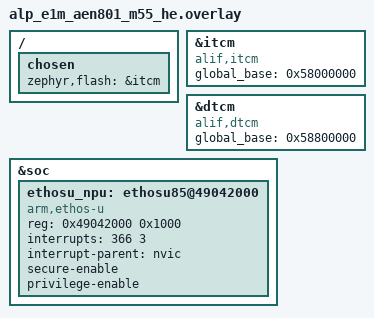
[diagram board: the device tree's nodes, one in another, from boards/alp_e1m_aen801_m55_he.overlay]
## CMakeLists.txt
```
# Copyright (c) 2026 Alp Lab AB
# SPDX-License-Identifier: Apache-2.0
#
# aen-npu-inference-alif -- the MATCHED-RUNTIME NPU inference app for the
# E1M-AEN801 (Ensemble E8, M55-HE).  A Vela-compiled int8 model runs through
# the Arm Apache-2.0 InferenceProcess wrapper (lib/ethosu_utils, the same
# runtime Alif's tflm_ethosu / executorch samples use) -> TFLM MicroInterpreter
# with AddEthosU() -> ethosu_invoke onto the Ethos-U85 (256-MAC).
#
# DIFFERENCE vs the sibling aen-npu-inference (which returned ethosu_invoke=1):
#   Both apps now enable CONFIG_ALP_SDK_INFERENCE_BACKEND_ETHOS_U_AEN
#   (prj.conf), which links alp-sdk's AEN Ethos-U backend
#   (src/backends/inference/ethos_u_aen.cpp) and its strong
#   ethosu_address_remap()/ethosu_config_select() overrides -- the actual fix,
#   measured 2026-07-28.  CONFIG_ARM_ETHOS_U (hal_alif's stale-signature
#   ethosu_callback.c) is deliberately NOT used by either app; see prj.conf.
#   This app additionally supports Vela-compiling with the ALIF system-config
#   (--config <ensemble_vela.ini> --system-config Ethos_U85_SRAM_Only
#   --memory-mode Sram_Only) via -DAEN_NPU_VELA_CONFIG, to match the
#   bench-validated command-stream layout exactly -- see gen_model.py for why
#   that config is NOT itself the ethosu_invoke=1 fix.  The overlay
#   re-`compatible`s the itcm/dtcm nodes onto alif,itcm/alif,dtcm and adds the
#   global_base props local_to_global() needs.
#
# Modules required at build time (pass via -DEXTRA_ZEPHYR_MODULES):
#   the alp-sdk checkout    (the SDK + ARM_ETHOS_U glue)
#   hal_alif                (the Alif HAL module -- ethosu_callback.c)
#   hal/ethos_u             (the Arm Ethos-U core driver lib)
#   lib/tflite-micro        (TFLM + the Ethos-U custom op)
#
# LICENSING (alp-sdk doctrine):
#   - lib/ethosu_utils/{inference_process.cpp,.hpp} + include/ethosu/InferenceRunner.h
#     are Apache-2.0 (Arm) -> VENDORED into this example (Tier-2, provenance hdr).
#   - The Alif Vela config (ensemble_vela.ini) + the subsys/modules/ethosu glue
#     are ALIF PROPRIETARY -> NOT vendored and NOT redistributed by alp-sdk.
#     Obtain ensemble_vela.ini from alp-sdk-internal and pass it explicitly:
#       -DAEN_NPU_VELA_CONFIG=<alp-sdk-internal>/.../ensemble_vela.ini
#     Without it Vela falls back to its built-in system-config and the emitted
#     command stream will NOT match the bench-validated E8 RTSS-HE runtime.

cmake_minimum_required(VERSION 3.20.0)

find_package(Zephyr REQUIRED HINTS $ENV{ZEPHYR_BASE})
project(aen_npu_inference_alif LANGUAGES C CXX)

# --------------------------------------------------------------------------
# Model-gen: Vela-compile the fixture for the U85 with the Alif system-config.
# --------------------------------------------------------------------------
set(AEN_NPU_VELA   "vela"
    CACHE FILEPATH "Vela compiler executable (on PATH, or override: -DAEN_NPU_VELA=<venv>/bin/vela)")
set(AEN_NPU_ACCEL  "ethos-u85-256"
    CACHE STRING   "Vela --accelerator-config (the AEN801 U85 is 256-MAC)")
set(AEN_NPU_MODEL  "${CMAKE_CURRENT_SOURCE_DIR}/../../../tests/fixtures/models/tiny_int8.tflite"
    CACHE FILEPATH "Input int8 .tflite to Vela-compile")
set(AEN_NPU_MODEL_NAME "tiny_int8_fixture"
    CACHE STRING   "Embedded model identity string")

# ALIF PROPRIETARY Vela config -- NOT redistributed by alp-sdk.  Obtain it from
# alp-sdk-internal and pass it via -DAEN_NPU_VELA_CONFIG=<path>/ensemble_vela.ini.
# When unset, Vela uses its built-in system-config (does NOT match the bench).
set(AEN_NPU_VELA_CONFIG ""
    CACHE FILEPATH "Path to the Alif Vela config .ini (ALIF PROPRIETARY -- from alp-sdk-internal)")
if(NOT AEN_NPU_VELA_CONFIG)
	message(WARNING
		"aen-npu-inference-alif: AEN_NPU_VELA_CONFIG unset -- Vela will use its "
		"built-in system-config and the emitted command stream will NOT match the "
		"bench-validated E8 runtime.  Pass -DAEN_NPU_VELA_CONFIG=<alp-sdk-internal>/ensemble_vela.ini.")
endif()
set(AEN_NPU_SYSTEM_CONFIG "Ethos_U85_SRAM_Only"
    CACHE STRING   "Vela --system-config (HE core, single SRAM region)")
set(AEN_NPU_MEMORY_MODE   "Sram_Only"
    CACHE STRING   "Vela --memory-mode (single region -> SRAM0)")

set(AEN_NPU_GEN_DIR "${CMAKE_CURRENT_BINARY_DIR}/model-gen")
set(AEN_NPU_MODEL_H "${AEN_NPU_GEN_DIR}/model.h")

set(_gen_args
	--vela          ${AEN_NPU_VELA}
	--accel         ${AEN_NPU_ACCEL}
	--model         ${AEN_NPU_MODEL}
	--name          ${AEN_NPU_MODEL_NAME}
	--build-dir     ${AEN_NPU_GEN_DIR}
	--out           ${AEN_NPU_MODEL_H}
)
# --system-config/--memory-mode name sections that live ONLY in the Alif
# proprietary ensemble_vela.ini (e.g. Ethos_U85_SRAM_Only) -- pass them ONLY
# when that config is supplied, else Vela errors "Section ... not found" against
# its built-in vela.ini.  Without the Alif config Vela falls back to its default
# system-config (the build succeeds; the command stream just won't match bench).
if(AEN_NPU_VELA_CONFIG)
	list(APPEND _gen_args --config ${AEN_NPU_VELA_CONFIG}
	     --system-config ${AEN_NPU_SYSTEM_CONFIG} --memory-mode ${AEN_NPU_MEMORY_MODE})
endif()

add_custom_command(
	OUTPUT  ${AEN_NPU_MODEL_H}
	COMMAND ${CMAKE_COMMAND} -E make_directory ${AEN_NPU_GEN_DIR}
	COMMAND ${PYTHON_EXECUTABLE} ${CMAKE_CURRENT_SOURCE_DIR}/gen_model.py ${_gen_args}
	DEPENDS ${AEN_NPU_MODEL} ${CMAKE_CURRENT_SOURCE_DIR}/gen_model.py
	COMMENT "aen-npu-inference-alif: Vela-compiling ${AEN_NPU_MODEL} for ${AEN_NPU_ACCEL} (${AEN_NPU_SYSTEM_CONFIG})"
	VERBATIM
)

# Configure-time generation (so the include path resolves on the first build).
if(NOT EXISTS ${AEN_NPU_MODEL_H})
	execute_process(
		COMMAND ${CMAKE_COMMAND} -E make_directory ${AEN_NPU_GEN_DIR}
		COMMAND ${PYTHON_EXECUTABLE} ${CMAKE_CURRENT_SOURCE_DIR}/gen_model.py ${_gen_args}
		RESULT_VARIABLE _gen_rc
	)
	if(NOT _gen_rc EQUAL 0)
		message(FATAL_ERROR "aen-npu-inference-alif: model-gen failed (rc=${_gen_rc})")
	endif()
endif()

add_custom_target(aen_npu_model DEPENDS ${AEN_NPU_MODEL_H})
add_dependencies(app aen_npu_model)

# --------------------------------------------------------------------------
# Publish hal_alif's common/include on the GLOBAL Zephyr include path so
# alp-sdk's AEN Ethos-U backend (src/backends/inference/ethos_u_aen.cpp,
# enabled by CONFIG_ALP_SDK_INFERENCE_BACKEND_ETHOS_U_AEN in prj.conf) can
# #include <soc_memory_map.h> (the local_to_global() its strong
# ethosu_address_remap uses).  NOT the hal_alif ethosu_callback.c library --
# that stays off (CONFIG_ARM_ETHOS_U unset, see prj.conf).
#
# WHY HERE and not via CONFIG_RTSS_HE: hal_alif's common/CMakeLists.txt adds
# that include dir only under `if(CONFIG_RTSS_HE OR CONFIG_RTSS_HP)`, but that
# same gate also compiles the TrustZone sources sau_tcm_ns_setup.c / tgu.c,
# which hard-#error without a non-secure `ns` DTS node (the fork has one; this
# RAM-run board does not, and inventing one would be inventing HW config).  We
# therefore publish ONLY the header directory and leave the TZ sources off.
# zephyr_include_directories() adds to the global interface, so the header is
# visible to the alp-sdk ethos_u_aen.cpp TU as well as the app.
zephyr_include_directories(${ZEPHYR_ALIF_MODULE_DIR}/common/include)

target_include_directories(app PRIVATE ${AEN_NPU_GEN_DIR})

# Apache-2.0 Arm InferenceProcess wrapper (vendored into this example).
target_include_directories(app PRIVATE ${CMAKE_CURRENT_SOURCE_DIR}/ethosu_utils)
target_sources(app PRIVATE
	src/main.cpp
	ethosu_utils/inference_process.cpp
)
```

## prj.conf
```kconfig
# SPDX-License-Identifier: Apache-2.0
#
# aen-npu-inference-alif -- MATCHED-RUNTIME FULL NPU inference on the
# E1M-AEN801 (Ensemble E8, M55-HE): a Vela-compiled int8 model (Alif
# system-config) through the Arm Apache InferenceProcess wrapper + TFLM's
# MicroInterpreter onto the Ethos-U85 (256-MAC), with the hal_alif Ethos-U
# callback linked.  Bench RAM-run over the Alp UART console (E1M edge UART0).

# --- TFLM + Ethos-U stack ---------------------------------------------------

# TFLM is C++17; the InferenceProcess wrapper + MicroInterpreter are C++.
CONFIG_CPP=y
CONFIG_STD_CPP17=y
# The Arm InferenceProcess wrapper uses std::string / std::vector / std::queue.
CONFIG_REQUIRES_FULL_LIBCPP=y

# TFLM module (MicroInterpreter, op resolver, reference kernels, and -- because
# the Ethos-U driver is enabled -- the Ethos-U custom-op kernel ethosu.cc whose
# Register_ETHOSU() -> ethosu_invoke dispatches onto the NPU).
CONFIG_TENSORFLOW_LITE_MICRO=y

# THE KEY DRIVER.  CONFIG_ETHOS_U compiles the Arm Ethos-U core driver
# (ethosu_driver.c / ethosu_device_u85.c -> ethosu_invoke + the NPU command
# stream) and the Zephyr frontend (drivers/misc/ethos_u, ETHOS_U_ARM, which
# auto-instantiates the arm,ethos-u node at POST_KERNEL).
CONFIG_ETHOS_U=y

# THE STRONG REMAP -- but NOT via hal_alif's ethosu_callback.c.
#
# CONFIG_ARM_ETHOS_U is the symbol hal_alif's drivers/CMakeLists.txt gates its
# ethosu_callback.c on (alp-sdk defines it in zephyr/Kconfig).  That file does
# carry the strong ethosu_address_remap = local_to_global we need -- BUT it was
# written against an OLDER Arm core driver and ALSO defines
# ethosu_flush_dcache / ethosu_invalidate_dcache with the OLD signature
# (uint32_t *p, size_t bytes).  The pinned hal_ethos_u core driver uses the NEW
# signature (const uint64_t *base_addr, const size_t *base_addr_size, int n) and
# upstream Zephyr's ethos_u_common.c provides matching strong versions, so
# compiling ethosu_callback.c causes a duplicate-symbol link error AND, if it
# won, the core driver would call its dcache hooks with mismatched args.
#
# So we keep ARM_ETHOS_U OFF (do not compile the stale vendor callback).  The
# strong ethosu_address_remap = local_to_global() now lives in alp-sdk's AEN
# Ethos-U backend (src/backends/inference/ethos_u_aen.cpp, enabled below) --
# it overrides the core driver's weak identity remap the same way, without
# the stale vendor file's dcache-hook clash.  local_to_global() itself is
# hal_alif's (soc_memory_map.h) -- nothing is re-authored.  The correct-
# signature dcache hooks come from upstream ethos_u_common.c (ETHOS_U_DCACHE
# below).  CONFIG_ARM_ETHOS_U is intentionally NOT set.

# alp-sdk AEN Ethos-U backend -- supplies the strong ethosu_address_remap()/
# ethosu_config_select() overrides (see src/backends/inference/ethos_u_aen.cpp).
# This app drives inference through the raw InferenceProcess wrapper, not
# <alp/inference.h>, but Zephyr links every alp-sdk TU with --whole-archive,
# so enabling the backend here is sufficient to link the overrides in.
CONFIG_ALP_SDK=y
CONFIG_ALP_SDK_INFERENCE_BACKEND_TFLM=y
CONFIG_ALP_SDK_INFERENCE_BACKEND_ETHOS_U_AEN=y
CONFIG_ALP_SDK_INFERENCE_ETHOS_U_VARIANT_U85=y

# Use upstream Zephyr's correct-signature cache hooks (ethos_u_common.c).  They
# are architectural no-ops under CONFIG_DCACHE=n, but keep the strong/weak
# resolution unambiguous and ready for a future DCACHE=y re-enable.
CONFIG_ETHOS_U_DCACHE=y

# NPU variant: the AE822 (E8) NPU is an Ethos-U85; pick the 256-MAC config so
# the core driver compiles ethosu_device_u85.c and the Vela ethos-u85-256
# command stream matches the silicon.  Agrees with gen_model.py --accel and
# the Alif --system-config Ethos_U85_SRAM_Only.
CONFIG_ETHOS_U85_256=y

# --- Heap / stack -----------------------------------------------------------

# TFLM + the Ethos-U Zephyr glue + the InferenceProcess wrapper allocate from
# the system heap (k_malloc for the per-thread heap/stacks/queue nodes).
CONFIG_HEAP_MEM_POOL_SIZE=65536

# AllocateTensors + Invoke run with the InferenceProcess on the main thread
# here (single job, no worker thread); give it the upstream sample's headroom.
CONFIG_MAIN_STACK_SIZE=16384

# --- DMA correctness (the #1 bench risk) ------------------------------------

# The Ethos-U is a DMA master reading the model + arena out of SRAM0.  With the
# M55 D-cache on, the CPU could leave the model/input dirty in cache or read
# stale output.  The hal_alif callback DOES provide clean/invalidate hooks
# (ethosu_flush/invalidate_dcache), but on this bench RAM-run we keep DCACHE=n
# (the eth_dwmac approach) so the NPU and CPU share a coherent view with no
# maintenance dependency.  (Follow-up: re-enable DCACHE -- the matched runtime's
# flush/invalidate hooks are already linked via ethosu_callback.c.)
CONFIG_DCACHE=n

# --- Console ----------------------------------------------------------------
# Console: Alp UART console -- E1M edge UART0 (Alif UART5, P3_4/P3_5, 115200
# 8N1, NS16550), the E1M-AEN801 carrier console. The board _defconfig already
# selects it; we set it explicitly here so the example is self-describing.
CONFIG_SERIAL=y
CONFIG_CONSOLE=y
CONFIG_UART_CONSOLE=y
CONFIG_UART_INTERRUPT_DRIVEN=y
# Serial-less bench? Comment the four lines above and uncomment these to read
# 'ram_console_buf' over SWD instead:
# CONFIG_RAM_CONSOLE=y
# CONFIG_RAM_CONSOLE_BUFFER_SIZE=2048
# CONFIG_UART_CONSOLE=n
CONFIG_PRINTK=y
# Keep logging off so the single RESULT line prints cleanly without log
# interleaving; the PASS gate reads that printk line, not log output.
CONFIG_LOG=n
```

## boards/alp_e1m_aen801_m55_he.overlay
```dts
/*
 * Copyright (c) 2026 Alp Lab AB
 * SPDX-License-Identifier: Apache-2.0
 *
 * aen-npu-inference-alif overlay for the E1M-AEN801 (Ensemble E8, M55-HE)
 * RAM-run -- the MATCHED-RUNTIME NPU inference overlay.  Adds:
 *   1. the Arm Ethos-U85 NPU node (base 0x49042000, IRQ 366);
 *   2. global_base on the ITCM/DTCM nodes (the missing piece for
 *      soc_memory_map.h local_to_global());
 *   3. the ITCM RAM-run chosen retarget.
 *
 * =====================  THE #1 BENCH RISK: DMA PLACEMENT  ====================
 * The Ethos-U85 is a DMA bus master: it reads the Vela command stream + weights
 * (the embedded model) and the intermediate tensors (the TFLM arena) over its
 * own AXI master, and writes the output tensor back the same way.  Those buffers
 * MUST live in memory the NPU can reach, and at the address the NPU is PROGRAMMED
 * with -- which is where local_to_global() comes in.
 *
 * The generated M55-HE board sets `zephyr,sram = &dtcm`.  DTCM is private to the
 * CPU; the model + arena are therefore tagged into the "SRAM0" linker region
 * (global on-chip SRAM @0x02000000, declared by the SoC dtsi sram0 node).  SRAM0
 * is already a global system address, so local_to_global() returns it unchanged
 * -- but for any ITCM/DTCM-resident buffer the strong remap is what converts the
 * CPU-local pointer into the global address the NPU's AXI master needs.
 * Combined with CONFIG_DCACHE=n (prj.conf), the CPU and NPU share a coherent
 * view of SRAM0 with no cache-maintenance calls.
 * ============================================================================
 */

/*
 * RAM-run: the SoC `select` puts code in XIP; retarget ROM to ITCM so the image
 * links + runs from RAM (J-Link loadbin+go, no reset).  PATH-REFERENCE form
 * (&itcm) -- the phandle-array form <&itcm> makes FLASH_SIZE=0 and overflows the
 * link.  Same as the regcheck overlay.
 */
/ {
	chosen {
		zephyr,flash = &itcm;
		/delete-property/ zephyr,code-partition;
	};
};

/*
 * global_base for local_to_global().
 *
 * hal_alif's soc_memory_map.h does DT_PROP(DT_NODELABEL(itcm), global_base) and
 * DT_PROP(DT_NODELABEL(dtcm), global_base).  The board's upstream itcm/dtcm
 * nodes are compatible "arm,itcm"/"arm,dtcm", whose binding has no global_base,
 * so the property is both undeclared and absent.  Re-`compatible` the nodes onto
 * the alp-sdk alif,itcm/alif,dtcm bindings (which declare global_base) and set
 * the E8 RTSS-HE global views, transcribed from the Apache-2.0 zephyr_alif fork
 * (dts/arm/alif/ensemble/common/ensemble_rtss_he.dtsi):
 *     ITCM global_base = 0x58000000, DTCM global_base = 0x58800000.
 * The zephyr,memory-region / reg are unchanged so the linker regions and the
 * RAM-run flash retarget above are unaffected.
 */
&itcm {
	compatible = "alif,itcm";
	global_base = <0x58000000>;
};

&dtcm {
	compatible = "alif,dtcm";
	global_base = <0x58800000>;
};

&soc {
	/*
	 * Arm Ethos-U85 NPU.  compatible "arm,ethos-u" (binding arm,ethos-u.yaml),
	 * driven by the Arm Ethos-U core driver's Zephyr frontend
	 * (drivers/misc/ethos_u/ethos_u_arm.c, DT_DRV_COMPAT arm_ethos_u).
	 * status="okay" makes DT_HAS_ARM_ETHOS_U_ENABLED true, which both builds
	 * the frontend and -- via CONFIG_ARM_ETHOS_U's `depends on` -- gates the
	 * NPU driver in.  ethosu_init() runs the NPU soft-reset before main(); the
	 * TFLM Ethos-U kernel later grabs this driver instance via
	 * ethosu_reserve_driver() inside Invoke().
	 *
	 * IRQ 366 + secure/privilege flags transcribed verbatim from the fork node
	 * (e4_e6_e8.dtsi ethosu1).  No `clocks` property: the fork's ethosu85 node
	 * carries none -- regcheck already confirmed the block is clocked
	 * (device_is_ready=1, ID=0x20007001).
	 */
	ethosu_npu: ethosu85@49042000 {
		compatible = "arm,ethos-u";
		reg = <0x49042000 0x1000>;
		interrupts = <366 3>;
		interrupt-parent = <&nvic>;
		secure-enable;
		privilege-enable;
		status = "okay";
	};
};
```

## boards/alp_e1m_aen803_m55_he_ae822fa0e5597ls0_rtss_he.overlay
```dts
/*
 * Copyright (c) 2026 Alp Lab AB
 * SPDX-License-Identifier: Apache-2.0
 *
 * aen-npu-inference-alif overlay for the E1M-AEN803 (Ensemble E8, M55-HE)
 * RAM-run -- the MATCHED-RUNTIME NPU inference overlay.  Adds:
 *   1. the Arm Ethos-U85 NPU node (base 0x49042000, IRQ 366);
 *   2. global_base on the ITCM/DTCM nodes (the missing piece for
 *      soc_memory_map.h local_to_global());
 *   3. the ITCM RAM-run chosen retarget.
 *
 * =====================  THE #1 BENCH RISK: DMA PLACEMENT  ====================
 * The Ethos-U85 is a DMA bus master: it reads the Vela command stream + weights
 * (the embedded model) and the intermediate tensors (the TFLM arena) over its
 * own AXI master, and writes the output tensor back the same way.  Those buffers
 * MUST live in memory the NPU can reach, and at the address the NPU is PROGRAMMED
 * with -- which is where local_to_global() comes in.
 *
 * The generated M55-HE board sets `zephyr,sram = &dtcm`.  DTCM is private to the
 * CPU; the model + arena are therefore tagged into the "SRAM0" linker region
 * (global on-chip SRAM @0x02000000, declared by the SoC dtsi sram0 node).  SRAM0
 * is already a global system address, so local_to_global() returns it unchanged
 * -- but for any ITCM/DTCM-resident buffer the strong remap is what converts the
 * CPU-local pointer into the global address the NPU's AXI master needs.
 * Combined with CONFIG_DCACHE=n (prj.conf), the CPU and NPU share a coherent
 * view of SRAM0 with no cache-maintenance calls.
 * ============================================================================
 */

/*
 * RAM-run: the SoC `select` puts code in XIP; retarget ROM to ITCM so the image
 * links + runs from RAM (J-Link loadbin+go, no reset).  PATH-REFERENCE form
 * (&itcm) -- the phandle-array form <&itcm> makes FLASH_SIZE=0 and overflows the
 * link.  Same as the regcheck overlay.
 */
/ {
	chosen {
		zephyr,flash = &itcm;
		/delete-property/ zephyr,code-partition;
	};
};

/*
 * global_base for local_to_global().
 *
 * hal_alif's soc_memory_map.h does DT_PROP(DT_NODELABEL(itcm), global_base) and
 * DT_PROP(DT_NODELABEL(dtcm), global_base).  The board's upstream itcm/dtcm
 * nodes are compatible "arm,itcm"/"arm,dtcm", whose binding has no global_base,
 * so the property is both undeclared and absent.  Re-`compatible` the nodes onto
 * the alp-sdk alif,itcm/alif,dtcm bindings (which declare global_base) and set
 * the E8 RTSS-HE global views, transcribed from the Apache-2.0 zephyr_alif fork
 * (dts/arm/alif/ensemble/common/ensemble_rtss_he.dtsi):
 *     ITCM global_base = 0x58000000, DTCM global_base = 0x58800000.
 * The zephyr,memory-region / reg are unchanged so the linker regions and the
 * RAM-run flash retarget above are unaffected.
 */
&itcm {
	compatible = "alif,itcm";
	global_base = <0x58000000>;
};

&dtcm {
	compatible = "alif,dtcm";
	global_base = <0x58800000>;
};

&soc {
	/*
	 * Arm Ethos-U85 NPU.  compatible "arm,ethos-u" (binding arm,ethos-u.yaml),
	 * driven by the Arm Ethos-U core driver's Zephyr frontend
	 * (drivers/misc/ethos_u/ethos_u_arm.c, DT_DRV_COMPAT arm_ethos_u).
	 * status="okay" makes DT_HAS_ARM_ETHOS_U_ENABLED true, which both builds
	 * the frontend and -- via CONFIG_ARM_ETHOS_U's `depends on` -- gates the
	 * NPU driver in.  ethosu_init() runs the NPU soft-reset before main(); the
	 * TFLM Ethos-U kernel later grabs this driver instance via
	 * ethosu_reserve_driver() inside Invoke().
	 *
	 * IRQ 366 + secure/privilege flags transcribed verbatim from the fork node
	 * (e4_e6_e8.dtsi ethosu1).  No `clocks` property: the fork's ethosu85 node
	 * carries none -- regcheck already confirmed the block is clocked
	 * (device_is_ready=1, ID=0x20007001).
	 */
	ethosu_npu: ethosu85@49042000 {
		compatible = "arm,ethos-u";
		reg = <0x49042000 0x1000>;
		interrupts = <366 3>;
		interrupt-parent = <&nvic>;
		secure-enable;
		privilege-enable;
		status = "okay";
	};
};
```

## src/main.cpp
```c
/*
 * Copyright (c) 2026 Alp Lab AB
 * SPDX-License-Identifier: Apache-2.0
 *
 * aen-npu-inference-alif -- MATCHED-RUNTIME on-silicon FULL NPU inference on the
 * E1M-AEN801 (Ensemble E8, M55-HE).  A Vela-compiled int8 model (compiled with
 * the ALIF system-config Ethos_U85_SRAM_Only) runs through the Arm Apache-2.0
 * InferenceProcess wrapper (lib/ethosu_utils -- the SAME runtime Alif's
 * tflm_ethosu / executorch samples use), which drives TFLM's MicroInterpreter
 * with AddEthosU() so the fused subgraph dispatches onto the Ethos-U85
 * (256-MAC) via ethosu_invoke.
 *
 * WHY THIS RUNS WHERE aen-npu-inference RETURNED ethosu_invoke=1:
 *   The Arm Ethos-U core driver's weak ethosu_address_remap()/
 *   ethosu_config_select() defaults leave ITCM/DTCM addresses untranslated and
 *   route the command stream + regions to the EXT AXI port -- wrong for this
 *   board's all-in-SRAM0 layout (bus-aborts on the first NPU fetch).  The fix
 *   is alp-sdk's AEN Ethos-U backend (src/backends/inference/ethos_u_aen.cpp),
 *   which supplies the STRONG overrides; CONFIG_ALP_SDK_INFERENCE_BACKEND_
 *   ETHOS_U_AEN=y (prj.conf) links it in -- see that file for the full
 *   explanation of both overrides, moved there from this file's previous
 *   in-app copies (measured 2026-07-28: the Vela --memory-mode flag alone is
 *   NOT the fix -- a byte-identical command stream to this app's sibling still
 *   returned ethosu_invoke=1 without the address-remap/config-select overrides).
 *
 * WHAT THIS PROVES (and what it does NOT):
 *   It proves the full matched path: a Vela-compiled .tflite ->
 *   InferenceProcess::runJob -> tflite::GetModel() -> MicroMutableOpResolver
 *   with AddEthosU() -> MicroInterpreter::Invoke() -> ethosu_invoke -> the NPU.
 *   A runJob()==false (success) + a populated output tensor is the "real
 *   inference ran on the NPU" evidence.
 *
 *   It does NOT validate model *accuracy* -- the embedded model is the in-tree
 *   FIXTURE tiny_int8.tflite (Vela: 1 NPU op, 100% NPU, 8 MACs), chosen so the
 *   bench app is hermetic and small.  A real-model end-to-end is the documented
 *   follow-up: rebuild with -DAEN_NPU_MODEL=<real.tflite>; the RESULT contract
 *   is model-agnostic.
 *
 * HOW WE OBSERVE (mirrors the regcheck dual-path):
 *   1. main() prints one RESULT PASS/FAIL line to the RAM console (read
 *      'ram_console_buf' over J-Link mem8, ASCII-decode).
 *   2. The same evidence is latched into file-scope volatile globals so it is
 *      readable by symbol over SWD even if the console were not captured.
 *
 * DMA placement: the model + arena live in SRAM0 (global on-chip SRAM
 * @0x02000000), NOT the M55-HE DTCM, because the NPU DMA cannot reach DTCM.
 * Combined with CONFIG_DCACHE=n, the CPU and NPU share a coherent view.  See
 * the overlay + gen_model.py.
 */

#include <cstdint>
#include <cstring>
#include <string>
#include <vector>

#include <zephyr/kernel.h>
#include <zephyr/device.h>
#include <zephyr/devicetree.h>
#include <zephyr/sys/printk.h>

/* Arm Apache-2.0 InferenceProcess wrapper (vendored: ethosu_utils/). */
#include "inference_process.hpp"

/* Generated by gen_model.py: networkModelData[] (rodata), NETWORK_MODEL_LEN,
 * NETWORK_MODEL_NAME, TENSOR_ARENA_SIZE, and the SRAM0 placement macros. */
#include "model.h"

using namespace InferenceProcess;

/* The Ethos-U node added by boards/alp_e1m_aen801_m55_he_ae822fa0e5597ls0_rtss_he.overlay. */
#define NPU_NODE DT_NODELABEL(ethosu_npu)

/*
 * The strong ethosu_address_remap()/ethosu_config_select() overrides that
 * make ethosu_invoke succeed on this board (NPU AXI address translation +
 * SRAM-port MEM_ATTR routing) used to live here.  They are now owned by
 * alp-sdk's AEN Ethos-U backend -- see src/backends/inference/ethos_u_aen.cpp
 * for the full explanation (WEAK-default behaviour, why it is wrong for an
 * all-in-SRAM0 layout, the bench-confirmed fault signature) and
 * CONFIG_ALP_SDK_INFERENCE_BACKEND_ETHOS_U_AEN in this app's prj.conf for how
 * they get linked into a build that never calls <alp/inference.h>.
 */

/*
 * Tensor arena -- DMA-reachable SRAM0, 16-byte aligned (NPU access
 * granularity).  TENSOR_ARENA_ATTR = __aligned(16) section("SRAM0").  This is
 * the working memory the MicroInterpreter (inside InferenceProcess) hands to
 * both the CPU reference kernels and the Ethos-U op; it MUST be NPU-reachable.
 */
TENSOR_ARENA_ATTR static uint8_t tensor_arena[TENSOR_ARENA_SIZE];

/*
 * DMA-reachable copy of the model.  networkModelData[] is const rodata
 * (initialized, in ITCM/flash); the Ethos-U reads the fused command stream +
 * weights out of the model via its own AXI master, so the bytes it executes
 * MUST live in NPU-reachable SRAM0.  An *initialized* array placed directly in
 * the SRAM0 custom section is NOT init-copied by Zephyr -> garbage -> bus
 * fault.  So keep the model in rodata and memcpy it into this uninitialized
 * SRAM0 buffer at startup.
 */
static uint8_t model_sram[NETWORK_MODEL_LEN] __aligned(NPU_ALIGN) __attribute__((section("SRAM0")));

/* Output capture buffer (SRAM0 -- the NPU writes the output tensor via DMA). */
static uint8_t output_sram[256] __aligned(NPU_ALIGN) __attribute__((section("SRAM0")));

/*
 * Latched evidence, readable by symbol over SWD independent of the RAM-console
 * decode.  volatile so the stores are not optimised away.
 */
volatile int      g_runjob_failed = -1;    /* runJob() return (false == OK)    */
volatile uint32_t g_in_bytes      = 0;     /* input tensor size in bytes       */
volatile uint32_t g_out_bytes     = 0;     /* output tensor size in bytes      */
volatile uint8_t  g_out_first[16] = { 0 }; /* first output bytes (raw int8)    */
volatile int      g_argmax        = -1;    /* argmax over the output bytes     */

int main(void)
{
	printk("\n=== aen-npu-inference-alif (matched runtime) ===\n");
	printk("model      : %s (%u bytes)\n", NETWORK_MODEL_NAME, (unsigned)NETWORK_MODEL_LEN);
	printk(
	    "arena      : %u bytes @ SRAM0 (%p)\n", (unsigned)TENSOR_ARENA_SIZE, (void *)tensor_arena);

	/*
	 * The Arm Ethos-U core driver auto-instantiates the NPU device at
	 * POST_KERNEL (the arm,ethos-u node is status="okay").  Reaching main()
	 * with device_is_ready()==1 means ethosu_init() (incl. the NPU soft reset)
	 * completed -- a prerequisite for ethosu_invoke to succeed.
	 */
	const struct device *npu       = DEVICE_DT_GET(NPU_NODE);
	bool                 npu_ready = device_is_ready(npu);
	printk(
	    "npu ready  : %d (Ethos-U85 @0x%08x)\n", (int)npu_ready, (unsigned)DT_REG_ADDR(NPU_NODE));

	/* Stage the model into DMA-reachable SRAM0 (see model_sram comment). */
	memcpy(model_sram, networkModelData, NETWORK_MODEL_LEN);

	/*
	 * Build the inference job.  InferenceProcess::runJob strictly validates
	 * input DataPtr.size == the network's input-tensor byte count, so the input
	 * size must match the model exactly.  The hermetic fixture tiny_int8 is a
	 * FULLY_CONNECTED with input shape [1,4] int8 = 4 bytes (output [1,2] int8 =
	 * 2 bytes); AEN_NPU_INPUT_BYTES defaults to that.  When a larger real model
	 * is swapped in via -DAEN_NPU_MODEL, set -DAEN_NPU_INPUT_BYTES to its input
	 * size -- a mismatch surfaces as RESULT FAIL with the network's expected
	 * size printed by runJob, so the operator re-tunes in one shot.  We stage a
	 * 4 KiB zeroed SRAM0 input region (DMA-reachable) and hand runJob a DataPtr
	 * of the exact input size; the extra staging headroom is harmless.
	 */
	static uint8_t input_sram[4096] __aligned(NPU_ALIGN) __attribute__((section("SRAM0")));
	memset(input_sram, 0, sizeof(input_sram));

#ifndef AEN_NPU_INPUT_BYTES
#define AEN_NPU_INPUT_BYTES 4 /* tiny_int8 fixture: input [1,4] int8 */
#endif
	const size_t input_bytes = AEN_NPU_INPUT_BYTES;

	g_in_bytes = (uint32_t)input_bytes;
	printk("input      : %u bytes (zero-filled, SRAM0)\n", (unsigned)input_bytes);

	InferenceJob job(std::string(NETWORK_MODEL_NAME),
	                 DataPtr((void *)model_sram, NETWORK_MODEL_LEN),
	                 { DataPtr((void *)input_sram, input_bytes) },
	                 { DataPtr((void *)output_sram, sizeof(output_sram)) },
	                 {});

	/*
	 * Run inference via the matched Arm InferenceProcess.  Internally:
	 *   GetModel -> MicroMutableOpResolver<1>::AddEthosU ->
	 *   MicroInterpreter(arena) -> AllocateTensors -> copy input ->
	 *   Invoke() (the fused Ethos-U op -> ethosu_invoke -> NPU IRQ) ->
	 *   copyOutput into the output DataPtr.
	 * runJob returns FALSE on success, TRUE on any failure.
	 */
	InferenceProcess::InferenceProcess inference(tensor_arena, TENSOR_ARENA_SIZE);
	bool                               failed = inference.runJob(job);
	g_runjob_failed                           = (int)failed;

	if (failed) {
		printk("RESULT FAIL: runJob failed (schema/alloc/invoke/size) "
		       "npu_ready=%d -- see log above for the exact stage\n",
		       (int)npu_ready);
		return 0;
	}

	/*
	 * runJob updated job.output[0].size to the actual output byte count and
	 * copied the NPU's output into output_sram.  Latch the first bytes +
	 * argmax for the RESULT line and the SWD symbol read.
	 */
	uint32_t out_bytes = (uint32_t)job.output[0].size;
	g_out_bytes        = out_bytes;

	uint32_t n           = out_bytes < 16u ? out_bytes : 16u;
	int      best_i      = -1;
	int      best_v      = -128; /* int8 floor */
	bool     any_nonzero = false;
	for (uint32_t i = 0; i < out_bytes; i++) {
		int8_t v = (int8_t)output_sram[i];
		if (i < n) {
			g_out_first[i] = (uint8_t)v;
		}
		if (v != 0) {
			any_nonzero = true;
		}
		if (v > best_v) {
			best_v = v;
			best_i = (int)i;
		}
	}
	g_argmax = best_i;

	printk("output     : %u bytes, argmax=%d (val=%d), first[0..%u]=",
	       (unsigned)out_bytes,
	       best_i,
	       best_v,
	       (unsigned)(n ? n - 1 : 0));
	for (uint32_t i = 0; i < n; i++) {
		printk("%02x ", g_out_first[i]);
	}
	printk("\n");

	/*
	 * PASS = inference completed AND the NPU actually produced a result.
	 * any_nonzero guards the silent-failure case (an all-zero output despite a
	 * runJob success would mean the NPU did not really write the tensor).
	 */
	bool ok = (!failed) && (out_bytes > 0) && any_nonzero;
	if (ok) {
		printk("RESULT PASS: NPU inference complete -- model=%s runJob=OK "
		       "out_bytes=%u argmax=%d npu_ready=%d\n",
		       NETWORK_MODEL_NAME,
		       (unsigned)out_bytes,
		       best_i,
		       (int)npu_ready);
	} else {
		printk("RESULT FAIL: runJob_failed=%d out_bytes=%u nonzero=%d "
		       "npu_ready=%d -- output not populated\n",
		       (int)failed,
		       (unsigned)out_bytes,
		       (int)any_nonzero,
		       (int)npu_ready);
	}

	return 0;
}
```
